# RX64M_CMT_Pilot register map
File version: 1.0
RX64M_CMT_Pilot peripheral registers generated from iodefine.h (pilot).
Registers are 16-bit, read-write, reset 0x0 unless marked. A register's access mark holds for its fields unless they carry their own. Offsets are from the block's base; lines under a group give offsets from that group; [hi:lo] are bit positions; {n}, {i} and the like mark numbered series; 'fields as' and 'values as' point back to an identical list; <NAME> marks a mode.

## Memory map
0x00088000 CMT size 0x12
0x00088002 CMT0 size 0x6
0x00088008 CMT1 size 0x6
0x00088012 CMT2 size 0x6
0x00088018 CMT3 size 0x6
0x00094200 CMTW0 size 0x28
0x00094280 CMTW1 size 0x28

## CMT
Base 0x00088000
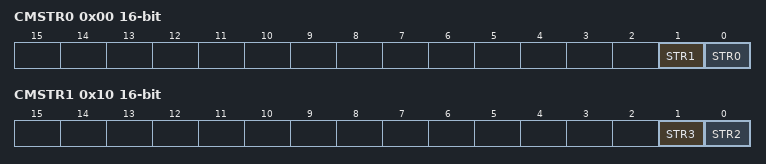
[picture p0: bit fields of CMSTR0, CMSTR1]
0x00 CMSTR0
  [1] STR1, [0] STR0
0x10 CMSTR1
  [1] STR3, [0] STR2

## CMT0
Base 0x00088002
Same registers: CMT1 0x00088008, CMT2 0x00088012, CMT3 0x00088018
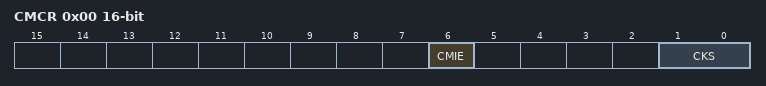
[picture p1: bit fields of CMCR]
0x00 CMCR
  [6] CMIE, [1:0] CKS
0x02 CMCNT
0x04 CMCOR reset 0xFFFF

## CMTW0
Base 0x00094200
Same registers: CMTW1 0x00094280
0x00 CMWSTR
  [0] STR
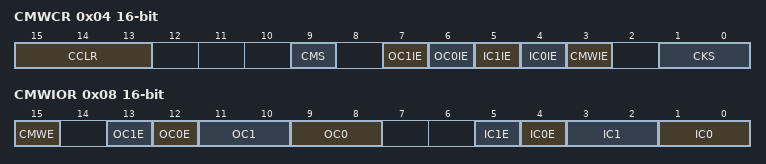
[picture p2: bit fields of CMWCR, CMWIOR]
0x04 CMWCR
  [15:13] CCLR, [9] CMS, [7] OC1IE, [6] OC0IE, [5] IC1IE, [4] IC0IE, [3] CMWIE, [1:0] CKS
0x08 CMWIOR
  [15] CMWE, [13] OC1E, [12] OC0E, [11:10] OC1, [9:8] OC0, [5] IC1E, [4] IC0E, [3:2] IC1, [1:0] IC0
0x10 CMWCNT 32-bit
0x14 CMWCOR 32-bit reset 0xFFFFFFFF
0x18 CMWICR0 32-bit ro
0x1C CMWICR1 32-bit ro
0x20 CMWOCR0 32-bit reset 0xFFFFFFFF
0x24 CMWOCR1 32-bit reset 0xFFFFFFFF
